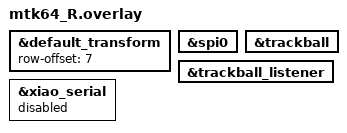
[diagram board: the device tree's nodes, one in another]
#include "mtk64.dtsi"
#include "mtk64_trackball.dtsi"

&default_transform {
    row-offset = <7>;
};

&spi0 {
    status = "okay";
};

&trackball {
    status = "okay";
};

&trackball_listener {
    status = "okay";
};

&xiao_serial {
    status = "disabled";
};
